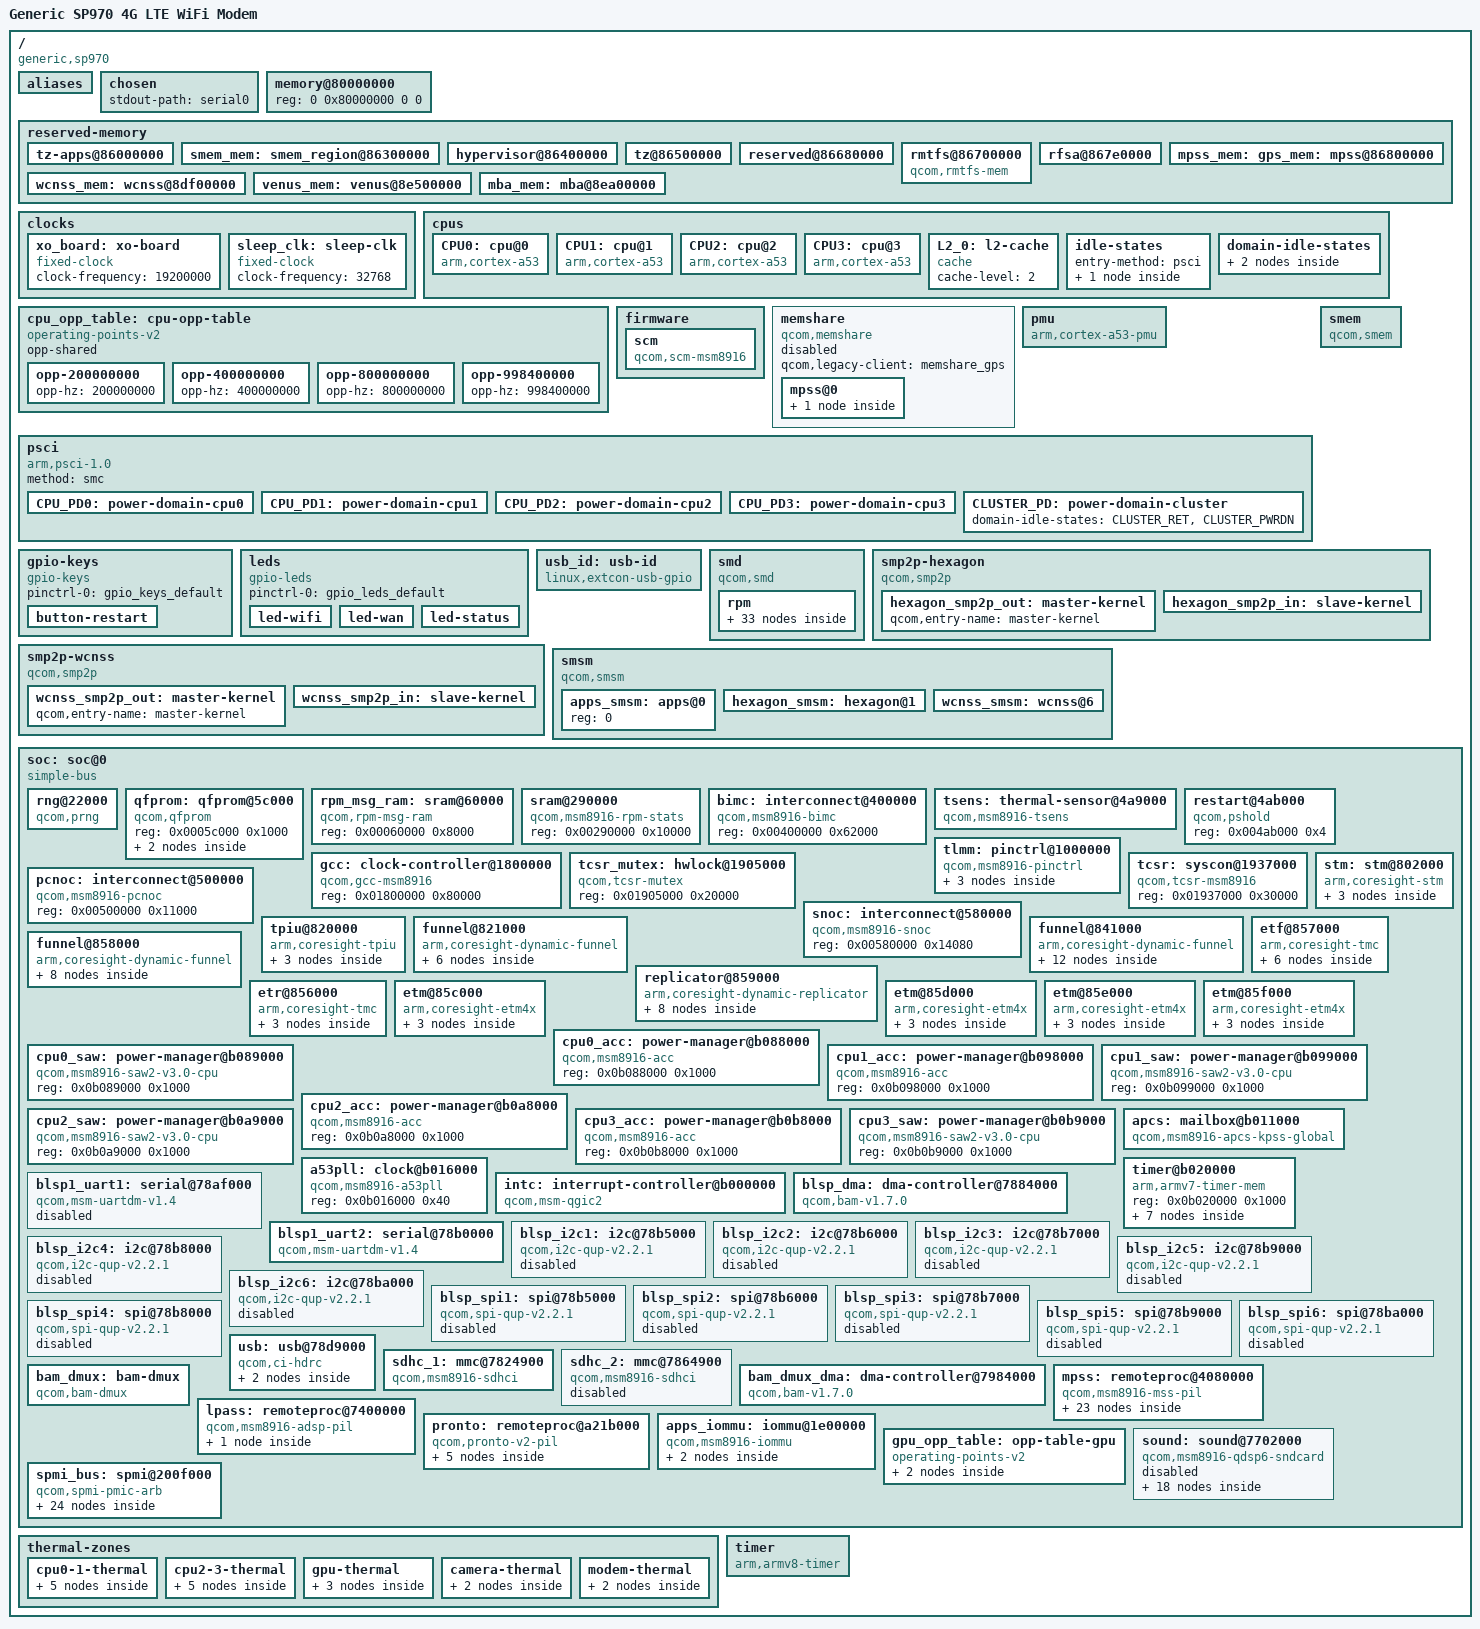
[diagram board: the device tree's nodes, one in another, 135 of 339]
// SPDX-License-Identifier: GPL-2.0-only

/dts-v1/;

#include <dt-bindings/clock/qcom,gcc-msm8916.h>
#include <dt-bindings/clock/qcom,rpmcc.h>
#include <dt-bindings/gpio/gpio.h>
#include <dt-bindings/input/input.h>
#include <dt-bindings/interrupt-controller/arm-gic.h>
#include <dt-bindings/leds/common.h>
#include <dt-bindings/pinctrl/qcom,pmic-gpio.h>
#include <dt-bindings/power/qcom-rpmpd.h>
#include <dt-bindings/reset/qcom,gcc-msm8916.h>
#include <dt-bindings/sound/apq8016-lpass.h>
#include <dt-bindings/sound/qcom,q6afe.h>
#include <dt-bindings/sound/qcom,q6asm.h>
#include <dt-bindings/sound/qcom,q6voice.h>
#include <dt-bindings/spmi/spmi.h>
#include <dt-bindings/thermal/thermal.h>

/ {
	model = "Generic SP970 4G LTE WiFi Modem";
	compatible = "generic,sp970", "qcom,msm8916";
	chassis-type = "embedded";

	interrupt-parent = <&intc>;
	#address-cells = <2>;
	#size-cells = <2>;

	aliases {
		serial0 = &blsp1_uart2;
		mmc0 = &sdhc_1;
		sdhc1 = &sdhc_1;
		sdhc2 = &sdhc_2;
	};

	chosen {
		stdout-path = "serial0";
	};

	memory@80000000 {
		device_type = "memory";
		reg = <0 0x80000000 0 0>;
	};

	reserved-memory {
		#address-cells = <2>;
		#size-cells = <2>;
		ranges;

		tz-apps@86000000 {
			reg = <0x0 0x86000000 0x0 0x300000>;
			no-map;
		};

		smem_mem: smem_region@86300000 {
			reg = <0x0 0x86300000 0x0 0x100000>;
			no-map;
		};

		hypervisor@86400000 {
			reg = <0x0 0x86400000 0x0 0x100000>;
			no-map;
		};

		tz@86500000 {
			reg = <0x0 0x86500000 0x0 0x180000>;
			no-map;
		};

		reserved@86680000 {
			reg = <0x0 0x86680000 0x0 0x80000>;
			no-map;
		};

		rmtfs@86700000 {
			compatible = "qcom,rmtfs-mem";
			reg = <0x0 0x86700000 0x0 0xe0000>;
			no-map;
			qcom,client-id = <1>;
		};

		rfsa@867e0000 {
			reg = <0x0 0x867e0000 0x0 0x20000>;
			no-map;
		};

		/* SP970 custom memory allocation for modem+GPS */
		mpss_mem: gps_mem: mpss@86800000 {
			reg = <0x0 0x86800000 0x0 0x5500000>;
			no-map;
		};

		wcnss_mem: wcnss@8df00000 {
			reg = <0x0 0x8df00000 0x0 0x600000>;
			no-map;
		};

		venus_mem: venus@8e500000 {
			reg = <0x0 0x8e500000 0x0 0x500000>;
			no-map;
		};

		mba_mem: mba@8ea00000 {
			reg = <0x0 0x8ea00000 0x0 0x100000>;
			no-map;
		};
	};

	clocks {
		xo_board: xo-board {
			compatible = "fixed-clock";
			#clock-cells = <0>;
			clock-frequency = <19200000>;
		};

		sleep_clk: sleep-clk {
			compatible = "fixed-clock";
			#clock-cells = <0>;
			clock-frequency = <32768>;
		};
	};

	cpus {
		#address-cells = <1>;
		#size-cells = <0>;

		CPU0: cpu@0 {
			device_type = "cpu";
			compatible = "arm,cortex-a53";
			reg = <0x0>;
			next-level-cache = <&L2_0>;
			enable-method = "psci";
			clocks = <&apcs>;
			operating-points-v2 = <&cpu_opp_table>;
			#cooling-cells = <2>;
			power-domains = <&CPU_PD0>;
			power-domain-names = "psci";
			qcom,acc = <&cpu0_acc>;
			qcom,saw = <&cpu0_saw>;
		};

		CPU1: cpu@1 {
			device_type = "cpu";
			compatible = "arm,cortex-a53";
			reg = <0x1>;
			next-level-cache = <&L2_0>;
			enable-method = "psci";
			clocks = <&apcs>;
			operating-points-v2 = <&cpu_opp_table>;
			#cooling-cells = <2>;
			power-domains = <&CPU_PD1>;
			power-domain-names = "psci";
			qcom,acc = <&cpu1_acc>;
			qcom,saw = <&cpu1_saw>;
		};

		CPU2: cpu@2 {
			device_type = "cpu";
			compatible = "arm,cortex-a53";
			reg = <0x2>;
			next-level-cache = <&L2_0>;
			enable-method = "psci";
			clocks = <&apcs>;
			operating-points-v2 = <&cpu_opp_table>;
			#cooling-cells = <2>;
			power-domains = <&CPU_PD2>;
			power-domain-names = "psci";
			qcom,acc = <&cpu2_acc>;
			qcom,saw = <&cpu2_saw>;
		};

		CPU3: cpu@3 {
			device_type = "cpu";
			compatible = "arm,cortex-a53";
			reg = <0x3>;
			next-level-cache = <&L2_0>;
			enable-method = "psci";
			clocks = <&apcs>;
			operating-points-v2 = <&cpu_opp_table>;
			#cooling-cells = <2>;
			power-domains = <&CPU_PD3>;
			power-domain-names = "psci";
			qcom,acc = <&cpu3_acc>;
			qcom,saw = <&cpu3_saw>;
		};

		L2_0: l2-cache {
			compatible = "cache";
			cache-level = <2>;
		};

		idle-states {
			entry-method = "psci";

			CPU_SLEEP_0: cpu-sleep-0 {
				compatible = "arm,idle-state";
				idle-state-name = "standalone-power-collapse";
				arm,psci-suspend-param = <0x40000002>;
				entry-latency-us = <130>;
				exit-latency-us = <150>;
				min-residency-us = <2000>;
				local-timer-stop;
			};
		};

		domain-idle-states {
			CLUSTER_RET: cluster-retention {
				compatible = "domain-idle-state";
				arm,psci-suspend-param = <0x41000012>;
				entry-latency-us = <500>;
				exit-latency-us = <500>;
				min-residency-us = <2000>;
			};

			CLUSTER_PWRDN: cluster-gdhs {
				compatible = "domain-idle-state";
				arm,psci-suspend-param = <0x41000032>;
				entry-latency-us = <2000>;
				exit-latency-us = <2000>;
				min-residency-us = <6000>;
			};
		};
	};

	cpu_opp_table: cpu-opp-table {
		compatible = "operating-points-v2";
		opp-shared;

		opp-200000000 {
			opp-hz = /bits/ 64 <200000000>;
		};

		opp-400000000 {
			opp-hz = /bits/ 64 <400000000>;
		};

		opp-800000000 {
			opp-hz = /bits/ 64 <800000000>;
		};

		opp-998400000 {
			opp-hz = /bits/ 64 <998400000>;
		};
	};

	firmware {
		scm: scm {
			compatible = "qcom,scm-msm8916", "qcom,scm";
			clocks = <&gcc GCC_CRYPTO_CLK>,
				 <&gcc GCC_CRYPTO_AXI_CLK>,
				 <&gcc GCC_CRYPTO_AHB_CLK>;
			clock-names = "core", "bus", "iface";
			#reset-cells = <1>;
			qcom,dload-mode = <&tcsr 0x6100>;
		};
	};

	/*
	 * Memshare disabled for SP970:
	 * The modem firmware sends a "query_size" memshare request for client ID 1,
	 * but doesn't actually use it. GPS only works if memshare is disabled or
	 * returns an error to the request.
	 */
	memshare: memshare {
		compatible = "qcom,memshare";
		qcom,legacy-client = <&memshare_gps>;
		status = "disabled";

		#address-cells = <1>;
		#size-cells = <0>;

		mpss@0 {
			reg = <0>;
			qcom,qrtr-node = <0>;

			#address-cells = <1>;
			#size-cells = <0>;

			memshare_gps: gps@0 {
				reg = <0>;
			};
		};
	};

	pmu {
		compatible = "arm,cortex-a53-pmu";
		interrupts = <GIC_PPI 7 (GIC_CPU_MASK_SIMPLE(4) | IRQ_TYPE_LEVEL_HIGH)>;
	};

	psci {
		compatible = "arm,psci-1.0";
		method = "smc";

		CPU_PD0: power-domain-cpu0 {
			#power-domain-cells = <0>;
			power-domains = <&CLUSTER_PD>;
			domain-idle-states = <&CPU_SLEEP_0>;
		};

		CPU_PD1: power-domain-cpu1 {
			#power-domain-cells = <0>;
			power-domains = <&CLUSTER_PD>;
			domain-idle-states = <&CPU_SLEEP_0>;
		};

		CPU_PD2: power-domain-cpu2 {
			#power-domain-cells = <0>;
			power-domains = <&CLUSTER_PD>;
			domain-idle-states = <&CPU_SLEEP_0>;
		};

		CPU_PD3: power-domain-cpu3 {
			#power-domain-cells = <0>;
			power-domains = <&CLUSTER_PD>;
			domain-idle-states = <&CPU_SLEEP_0>;
		};

		CLUSTER_PD: power-domain-cluster {
			#power-domain-cells = <0>;
			domain-idle-states = <&CLUSTER_RET>, <&CLUSTER_PWRDN>;
		};
	};

	/* SP970 specific hardware */
	gpio-keys {
		compatible = "gpio-keys";
		pinctrl-names = "default";
		pinctrl-0 = <&gpio_keys_default>;

		button-restart {
			label = "Restart";
			gpios = <&tlmm 107 GPIO_ACTIVE_LOW>;
			linux,code = <KEY_RESTART>;
			debounce-interval = <15>;
		};
	};

	leds {
		compatible = "gpio-leds";
		pinctrl-names = "default";
		pinctrl-0 = <&gpio_leds_default>;

		led-wifi {
			color = <LED_COLOR_ID_BLUE>;
			function = LED_FUNCTION_WLAN;
			gpios = <&tlmm 28 GPIO_ACTIVE_HIGH>;
			linux,default-trigger = "phy0tx";
			default-state = "off";
		};

		led-wan {
			color = <LED_COLOR_ID_GREEN>;
			function = LED_FUNCTION_WAN;
			gpios = <&tlmm 10 GPIO_ACTIVE_HIGH>;
			default-state = "off";
		};

		led-status {
			color = <LED_COLOR_ID_RED>;
			function = LED_FUNCTION_STATUS;
			gpios = <&tlmm 9 GPIO_ACTIVE_HIGH>;
			linux,default-trigger = "heartbeat";
			default-state = "on";
		};
	};

	usb_id: usb-id {
		compatible = "linux,extcon-usb-gpio";
		id-gpios = <&tlmm 110 GPIO_ACTIVE_HIGH>;
		pinctrl-names = "default";
		pinctrl-0 = <&usb_id_default>;
	};

	smd {
		compatible = "qcom,smd";

		rpm {
			interrupts = <GIC_SPI 168 IRQ_TYPE_EDGE_RISING>;
			qcom,ipc = <&apcs 8 0>;
			qcom,smd-edge = <15>;

			rpm_requests: rpm-requests {
				compatible = "qcom,rpm-msm8916";
				qcom,smd-channels = "rpm_requests";

				rpmcc: clock-controller {
					compatible = "qcom,rpmcc-msm8916", "qcom,rpmcc";
					#clock-cells = <1>;
				};

				rpmpd: power-controller {
					compatible = "qcom,msm8916-rpmpd";
					#power-domain-cells = <1>;
					operating-points-v2 = <&rpmpd_opp_table>;

					rpmpd_opp_table: opp-table {
						compatible = "operating-points-v2";

						rpmpd_opp_ret: opp1 {
							opp-level = <RPM_SMD_LEVEL_RETENTION>;
						};

						rpmpd_opp_ret_plus: opp2 {
							opp-level = <RPM_SMD_LEVEL_RETENTION_PLUS>;
						};

						rpmpd_opp_min_svs: opp3 {
							opp-level = <RPM_SMD_LEVEL_MIN_SVS>;
						};

						rpmpd_opp_low_svs: opp4 {
							opp-level = <RPM_SMD_LEVEL_LOW_SVS>;
						};

						rpmpd_opp_svs: opp5 {
							opp-level = <RPM_SMD_LEVEL_SVS>;
						};

						rpmpd_opp_svs_plus: opp6 {
							opp-level = <RPM_SMD_LEVEL_SVS_PLUS>;
						};

						rpmpd_opp_nom: opp7 {
							opp-level = <RPM_SMD_LEVEL_NOM>;
						};

						rpmpd_opp_nom_plus: opp8 {
							opp-level = <RPM_SMD_LEVEL_NOM_PLUS>;
						};

						rpmpd_opp_turbo: opp9 {
							opp-level = <RPM_SMD_LEVEL_TURBO>;
						};
					};
				};

				smd_rpm_regulators: pm8916-regulators {
					compatible = "qcom,rpm-pm8916-regulators";
					
					vdd_l1_l2_l3-supply = <&pm8916_s3>;
					vdd_l4_l5_l6-supply = <&pm8916_s4>;
					vdd_l7-supply = <&pm8916_s4>;

					pm8916_s3: s3 {
						regulator-min-microvolt = <1200000>;
						regulator-max-microvolt = <1300000>;
					};

					pm8916_s4: s4 {
						regulator-min-microvolt = <1800000>;
						regulator-max-microvolt = <2100000>;
					};

					pm8916_l1: l1 {
						regulator-min-microvolt = <1225000>;
						regulator-max-microvolt = <1225000>;
					};

					pm8916_l2: l2 {
						regulator-min-microvolt = <1200000>;
						regulator-max-microvolt = <1200000>;
					};

					pm8916_l4: l4 {
						regulator-min-microvolt = <2050000>;
						regulator-max-microvolt = <2050000>;
					};

					pm8916_l5: l5 {
						regulator-min-microvolt = <1800000>;
						regulator-max-microvolt = <1800000>;
					};

					pm8916_l6: l6 {
						regulator-min-microvolt = <1800000>;
						regulator-max-microvolt = <1800000>;
					};

					pm8916_l7: l7 {
						regulator-min-microvolt = <1800000>;
						regulator-max-microvolt = <1800000>;
					};

					pm8916_l8: l8 {
						regulator-min-microvolt = <2850000>;
						regulator-max-microvolt = <2900000>;
					};

					pm8916_l9: l9 {
						regulator-min-microvolt = <3300000>;
						regulator-max-microvolt = <3300000>;
					};

					pm8916_l10: l10 {
						regulator-min-microvolt = <2700000>;
						regulator-max-microvolt = <2800000>;
					};

					pm8916_l11: l11 {
						regulator-min-microvolt = <1800000>;
						regulator-max-microvolt = <2950000>;
						regulator-allow-set-load;
						regulator-system-load = <200000>;
					};

					pm8916_l12: l12 {
						regulator-min-microvolt = <1800000>;
						regulator-max-microvolt = <2950000>;
					};

					pm8916_l13: l13 {
						regulator-min-microvolt = <3075000>;
						regulator-max-microvolt = <3075000>;
					};

					pm8916_l14: l14 {
						regulator-min-microvolt = <1800000>;
						regulator-max-microvolt = <3300000>;
					};

					pm8916_l15: l15 {
						regulator-min-microvolt = <1800000>;
						regulator-max-microvolt = <3300000>;
					};

					pm8916_l16: l16 {
						regulator-min-microvolt = <1800000>;
						regulator-max-microvolt = <3300000>;
					};

					pm8916_l17: l17 {
						regulator-min-microvolt = <2850000>;
						regulator-max-microvolt = <2850000>;
						regulator-always-on;
					};

					pm8916_l18: l18 {
						regulator-min-microvolt = <2700000>;
						regulator-max-microvolt = <2700000>;
					};
				};
			};
		};
	};

	smem {
		compatible = "qcom,smem";
		memory-region = <&smem_mem>;
		qcom,rpm-msg-ram = <&rpm_msg_ram>;
		hwlocks = <&tcsr_mutex 3>;
	};

	smp2p-hexagon {
		compatible = "qcom,smp2p";
		qcom,smem = <435>, <428>;
		interrupts = <GIC_SPI 27 IRQ_TYPE_EDGE_RISING>;
		qcom,ipc = <&apcs 8 14>;
		qcom,local-pid = <0>;
		qcom,remote-pid = <1>;

		hexagon_smp2p_out: master-kernel {
			qcom,entry-name = "master-kernel";
			#qcom,smem-state-cells = <1>;
		};

		hexagon_smp2p_in: slave-kernel {
			qcom,entry-name = "slave-kernel";
			interrupt-controller;
			#interrupt-cells = <2>;
		};
	};

	smp2p-wcnss {
		compatible = "qcom,smp2p";
		qcom,smem = <451>, <431>;
		interrupts = <GIC_SPI 143 IRQ_TYPE_EDGE_RISING>;
		qcom,ipc = <&apcs 8 18>;
		qcom,local-pid = <0>;
		qcom,remote-pid = <4>;

		wcnss_smp2p_out: master-kernel {
			qcom,entry-name = "master-kernel";
			#qcom,smem-state-cells = <1>;
		};

		wcnss_smp2p_in: slave-kernel {
			qcom,entry-name = "slave-kernel";
			interrupt-controller;
			#interrupt-cells = <2>;
		};
	};

	smsm {
		compatible = "qcom,smsm";
		#address-cells = <1>;
		#size-cells = <0>;
		qcom,ipc-1 = <&apcs 8 13>;
		qcom,ipc-3 = <&apcs 8 19>;

		apps_smsm: apps@0 {
			reg = <0>;
			#qcom,smem-state-cells = <1>;
		};

		hexagon_smsm: hexagon@1 {
			reg = <1>;
			interrupts = <GIC_SPI 26 IRQ_TYPE_EDGE_RISING>;
			interrupt-controller;
			#interrupt-cells = <2>;
		};

		wcnss_smsm: wcnss@6 {
			reg = <6>;
			interrupts = <GIC_SPI 144 IRQ_TYPE_EDGE_RISING>;
			interrupt-controller;
			#interrupt-cells = <2>;
		};
	};

	soc: soc@0 {
		compatible = "simple-bus";
		#address-cells = <1>;
		#size-cells = <1>;
		ranges = <0 0 0 0xffffffff>;

		rng@22000 {
			compatible = "qcom,prng";
			reg = <0x00022000 0x200>;
			clocks = <&gcc GCC_PRNG_AHB_CLK>;
			clock-names = "core";
		};

		qfprom: qfprom@5c000 {
			compatible = "qcom,qfprom";
			reg = <0x0005c000 0x1000>;
			#address-cells = <1>;
			#size-cells = <1>;

			tsens_caldata: caldata@d0 {
				reg = <0xd0 0x8>;
			};

			tsens_calsel: calsel@ec {
				reg = <0xec 0x4>;
			};
		};

		rpm_msg_ram: sram@60000 {
			compatible = "qcom,rpm-msg-ram";
			reg = <0x00060000 0x8000>;
		};

		sram@290000 {
			compatible = "qcom,msm8916-rpm-stats";
			reg = <0x00290000 0x10000>;
		};

		bimc: interconnect@400000 {
			compatible = "qcom,msm8916-bimc";
			reg = <0x00400000 0x62000>;
			#interconnect-cells = <1>;
		};

		tsens: thermal-sensor@4a9000 {
			compatible = "qcom,msm8916-tsens", "qcom,tsens-v0_1";
			reg = <0x004a9000 0x1000>,
			      <0x004a8000 0x1000>;
			nvmem-cells = <&tsens_caldata>, <&tsens_calsel>;
			nvmem-cell-names = "calib", "calib_sel";
			#qcom,sensors = <5>;
			interrupts = <GIC_SPI 184 IRQ_TYPE_LEVEL_HIGH>;
			interrupt-names = "uplow";
			#thermal-sensor-cells = <1>;
		};

		restart@4ab000 {
			compatible = "qcom,pshold";
			reg = <0x004ab000 0x4>;
		};

		tlmm: pinctrl@1000000 {
			compatible = "qcom,msm8916-pinctrl";
			reg = <0x01000000 0x300000>;
			interrupts = <GIC_SPI 208 IRQ_TYPE_LEVEL_HIGH>;
			gpio-controller;
			gpio-ranges = <&tlmm 0 0 122>;
			#gpio-cells = <2>;
			interrupt-controller;
			#interrupt-cells = <2>;

			/* SP970 specific pinctrl states */
			gpio_keys_default: gpio-keys-default-state {
				pins = "gpio107";
				function = "gpio";
				drive-strength = <2>;
				bias-pull-up;
			};

			gpio_leds_default: gpio-leds-default-state {
				pins = "gpio9", "gpio10", "gpio28";
				function = "gpio";
				drive-strength = <2>;
				bias-disable;
			};

			usb_id_default: usb-id-default-state {
				pins = "gpio110";
				function = "gpio";
				drive-strength = <8>;
				bias-pull-up;
			};
		};

		gcc: clock-controller@1800000 {
			compatible = "qcom,gcc-msm8916";
			#clock-cells = <1>;
			#reset-cells = <1>;
			#power-domain-cells = <1>;
			reg = <0x01800000 0x80000>;
		};

		tcsr_mutex: hwlock@1905000 {
			compatible = "qcom,tcsr-mutex";
			reg = <0x01905000 0x20000>;
			#hwlock-cells = <1>;
		};

		tcsr: syscon@1937000 {
			compatible = "qcom,tcsr-msm8916", "syscon";
			reg = <0x01937000 0x30000>;
		};

		pcnoc: interconnect@500000 {
			compatible = "qcom,msm8916-pcnoc";
			reg = <0x00500000 0x11000>;
			#interconnect-cells = <1>;
		};

		snoc: interconnect@580000 {
			compatible = "qcom,msm8916-snoc";
			reg = <0x00580000 0x14080>;
			#interconnect-cells = <1>;
		};

		stm: stm@802000 {
			compatible = "arm,coresight-stm", "arm,primecell";
			reg = <0x00802000 0x1000>,
			      <0x09280000 0x180000>;
			reg-names = "stm-base", "stm-stimulus-base";
			clocks = <&rpmcc RPM_QDSS_CLK>, <&rpmcc RPM_QDSS_A_CLK>;
			clock-names = "apb_pclk", "atclk";

			out-ports {
				port {
					stm_out: endpoint {
						remote-endpoint = <&funnel0_in7>;
					};
				};
			};
		};

		tpiu@820000 {
			compatible = "arm,coresight-tpiu", "arm,primecell";
			reg = <0x00820000 0x1000>;
			clocks = <&rpmcc RPM_QDSS_CLK>, <&rpmcc RPM_QDSS_A_CLK>;
			clock-names = "apb_pclk", "atclk";

			in-ports {
				port {
					tpiu_in: endpoint {
						remote-endpoint = <&replicator_out1>;
					};
				};
			};
		};

		funnel@821000 {
			compatible = "arm,coresight-dynamic-funnel", "arm,primecell";
			reg = <0x00821000 0x1000>;
			clocks = <&rpmcc RPM_QDSS_CLK>, <&rpmcc RPM_QDSS_A_CLK>;
			clock-names = "apb_pclk", "atclk";

			in-ports {
				#address-cells = <1>;
				#size-cells = <0>;

				port@7 {
					reg = <7>;
					funnel0_in7: endpoint {
						remote-endpoint = <&stm_out>;
					};
				};
			};

			out-ports {
				port {
					funnel0_out: endpoint {
						remote-endpoint = <&merge_funnel_in0>;
					};
				};
			};
		};

		funnel@841000 {
			compatible = "arm,coresight-dynamic-funnel", "arm,primecell";
			reg = <0x00841000 0x1000>;
			clocks = <&rpmcc RPM_QDSS_CLK>, <&rpmcc RPM_QDSS_A_CLK>;
			clock-names = "apb_pclk", "atclk";

			in-ports {
				#address-cells = <1>;
				#size-cells = <0>;

				port@4 {
					reg = <4>;
					funnel1_in4: endpoint {
						remote-endpoint = <&etm3_out>;
					};
				};

				port@5 {
					reg = <5>;
					funnel1_in5: endpoint {
						remote-endpoint = <&etm2_out>;
					};
				};

				port@6 {
					reg = <6>;
					funnel1_in6: endpoint {
						remote-endpoint = <&etm1_out>;
					};
				};

				port@7 {
					reg = <7>;
					funnel1_in7: endpoint {
						remote-endpoint = <&etm0_out>;
					};
				};
			};

			out-ports {
				port {
					funnel1_out: endpoint {
						remote-endpoint = <&merge_funnel_in1>;
					};
				};
			};
		};

		funnel@858000 {
			compatible = "arm,coresight-dynamic-funnel", "arm,primecell";
			reg = <0x00858000 0x1000>;
			clocks = <&rpmcc RPM_QDSS_CLK>, <&rpmcc RPM_QDSS_A_CLK>;
			clock-names = "apb_pclk", "atclk";

			in-ports {
				#address-cells = <1>;
				#size-cells = <0>;

				port@0 {
					reg = <0>;
					merge_funnel_in0: endpoint {
						remote-endpoint = <&funnel0_out>;
					};
				};

				port@1 {
					reg = <1>;
					merge_funnel_in1: endpoint {
						remote-endpoint = <&funnel1_out>;
					};
				};
			};

			out-ports {
				port {
					merge_funnel_out: endpoint {
						remote-endpoint = <&etf_in>;
					};
				};
			};
		};

		replicator@859000 {
			compatible = "arm,coresight-dynamic-replicator", "arm,primecell";
			reg = <0x00859000 0x1000>;
			clocks = <&rpmcc RPM_QDSS_CLK>, <&rpmcc RPM_QDSS_A_CLK>;
			clock-names = "apb_pclk", "atclk";

			in-ports {
				port {
					replicator_in: endpoint {
						remote-endpoint = <&etf_out>;
					};
				};
			};

			out-ports {
				#address-cells = <1>;
				#size-cells = <0>;

				port@0 {
					reg = <0>;
					replicator_out0: endpoint {
						remote-endpoint = <&etr_in>;
					};
				};

				port@1 {
					reg = <1>;
					replicator_out1: endpoint {
						remote-endpoint = <&tpiu_in>;
					};
				};
			};
		};

		etf@857000 {
			compatible = "arm,coresight-tmc", "arm,primecell";
			reg = <0x00857000 0x1000>;
			clocks = <&rpmcc RPM_QDSS_CLK>, <&rpmcc RPM_QDSS_A_CLK>;
			clock-names = "apb_pclk", "atclk";

			in-ports {
				port {
					etf_in: endpoint {
						remote-endpoint = <&merge_funnel_out>;
					};
				};
			};

			out-ports {
				port {
					etf_out: endpoint {
						remote-endpoint = <&replicator_in>;
					};
				};
			};
		};

		etr@856000 {
			compatible = "arm,coresight-tmc", "arm,primecell";
			reg = <0x00856000 0x1000>;
			clocks = <&rpmcc RPM_QDSS_CLK>, <&rpmcc RPM_QDSS_A_CLK>;
			clock-names = "apb_pclk", "atclk";

			in-ports {
				port {
					etr_in: endpoint {
						remote-endpoint = <&replicator_out0>;
					};
				};
			};
		};

		etm@85c000 {
			compatible = "arm,coresight-etm4x", "arm,primecell";
			reg = <0x0085c000 0x1000>;
			clocks = <&rpmcc RPM_QDSS_CLK>, <&rpmcc RPM_QDSS_A_CLK>;
			clock-names = "apb_pclk", "atclk";
			cpu = <&CPU0>;

			out-ports {
				port {
					etm0_out: endpoint {
						remote-endpoint = <&funnel1_in7>;
					};
				};
			};
		};

		etm@85d000 {
			compatible = "arm,coresight-etm4x", "arm,primecell";
			reg = <0x0085d000 0x1000>;
			clocks = <&rpmcc RPM_QDSS_CLK>, <&rpmcc RPM_QDSS_A_CLK>;
			clock-names = "apb_pclk", "atclk";
			cpu = <&CPU1>;

			out-ports {
				port {
					etm1_out: endpoint {
						remote-endpoint = <&funnel1_in6>;
					};
				};
			};
		};

		etm@85e000 {
			compatible = "arm,coresight-etm4x", "arm,primecell";
			reg = <0x0085e000 0x1000>;
			clocks = <&rpmcc RPM_QDSS_CLK>, <&rpmcc RPM_QDSS_A_CLK>;
			clock-names = "apb_pclk", "atclk";
			cpu = <&CPU2>;

			out-ports {
				port {
					etm2_out: endpoint {
						remote-endpoint = <&funnel1_in5>;
					};
				};
			};
		};

		etm@85f000 {
			compatible = "arm,coresight-etm4x", "arm,primecell";
			reg = <0x0085f000 0x1000>;
			clocks = <&rpmcc RPM_QDSS_CLK>, <&rpmcc RPM_QDSS_A_CLK>;
			clock-names = "apb_pclk", "atclk";
			cpu = <&CPU3>;

			out-ports {
				port {
					etm3_out: endpoint {
						remote-endpoint = <&funnel1_in4>;
					};
				};
			};
		};

		cpu0_acc: power-manager@b088000 {
			compatible = "qcom,msm8916-acc";
			reg = <0x0b088000 0x1000>;
		};

		cpu0_saw: power-manager@b089000 {
			compatible = "qcom,msm8916-saw2-v3.0-cpu", "qcom,saw2";
			reg = <0x0b089000 0x1000>;
		};

		cpu1_acc: power-manager@b098000 {
			compatible = "qcom,msm8916-acc";
			reg = <0x0b098000 0x1000>;
		};

		cpu1_saw: power-manager@b099000 {
			compatible = "qcom,msm8916-saw2-v3.0-cpu", "qcom,saw2";
			reg = <0x0b099000 0x1000>;
		};

		cpu2_acc: power-manager@b0a8000 {
			compatible = "qcom,msm8916-acc";
			reg = <0x0b0a8000 0x1000>;
		};

		cpu2_saw: power-manager@b0a9000 {
			compatible = "qcom,msm8916-saw2-v3.0-cpu", "qcom,saw2";
			reg = <0x0b0a9000 0x1000>;
		};

		cpu3_acc: power-manager@b0b8000 {
			compatible = "qcom,msm8916-acc";
			reg = <0x0b0b8000 0x1000>;
		};

		cpu3_saw: power-manager@b0b9000 {
			compatible = "qcom,msm8916-saw2-v3.0-cpu", "qcom,saw2";
			reg = <0x0b0b9000 0x1000>;
		};

		apcs: mailbox@b011000 {
			compatible = "qcom,msm8916-apcs-kpss-global", "syscon";
			reg = <0x0b011000 0x1000>;
			#mbox-cells = <1>;
			clocks = <&a53pll>, <&gcc GPLL0_VOTE>;
			clock-names = "pll", "aux";
			#clock-cells = <0>;
		};

		a53pll: clock@b016000 {
			compatible = "qcom,msm8916-a53pll";
			reg = <0x0b016000 0x40>;
			#clock-cells = <0>;
		};

		timer@b020000 {
			compatible = "arm,armv7-timer-mem";
			reg = <0x0b020000 0x1000>;
			#address-cells = <1>;
			#size-cells = <1>;
			ranges;

			frame@b021000 {
				reg = <0x0b021000 0x1000>,
				      <0x0b022000 0x1000>;
				frame-number = <0>;
				interrupts = <GIC_SPI 8 IRQ_TYPE_LEVEL_HIGH>,
					     <GIC_SPI 7 IRQ_TYPE_LEVEL_HIGH>;
			};

			frame@b023000 {
				reg = <0x0b023000 0x1000>;
				frame-number = <1>;
				interrupts = <GIC_SPI 9 IRQ_TYPE_LEVEL_HIGH>;
				status = "disabled";
			};

			frame@b024000 {
				reg = <0x0b024000 0x1000>;
				frame-number = <2>;
				interrupts = <GIC_SPI 10 IRQ_TYPE_LEVEL_HIGH>;
				status = "disabled";
			};

			frame@b025000 {
				reg = <0x0b025000 0x1000>;
				frame-number = <3>;
				interrupts = <GIC_SPI 11 IRQ_TYPE_LEVEL_HIGH>;
				status = "disabled";
			};

			frame@b026000 {
				reg = <0x0b026000 0x1000>;
				frame-number = <4>;
				interrupts = <GIC_SPI 12 IRQ_TYPE_LEVEL_HIGH>;
				status = "disabled";
			};

			frame@b027000 {
				reg = <0x0b027000 0x1000>;
				frame-number = <5>;
				interrupts = <GIC_SPI 13 IRQ_TYPE_LEVEL_HIGH>;
				status = "disabled";
			};

			frame@b028000 {
				reg = <0x0b028000 0x1000>;
				frame-number = <6>;
				interrupts = <GIC_SPI 14 IRQ_TYPE_LEVEL_HIGH>;
				status = "disabled";
			};
		};

		intc: interrupt-controller@b000000 {
			compatible = "qcom,msm-qgic2";
			reg = <0x0b000000 0x1000>, <0x0b002000 0x1000>;
			interrupt-controller;
			#interrupt-cells = <3>;
		};

		blsp_dma: dma-controller@7884000 {
			compatible = "qcom,bam-v1.7.0";
			reg = <0x07884000 0x1f000>;
			interrupts = <GIC_SPI 238 IRQ_TYPE_LEVEL_HIGH>;
			clocks = <&gcc GCC_BLSP1_AHB_CLK>;
			clock-names = "bam_clk";
			#dma-cells = <1>;
			qcom,ee = <0>;
			status = "okay";
		};

		blsp1_uart1: serial@78af000 {
			compatible = "qcom,msm-uartdm-v1.4", "qcom,msm-uartdm";
			reg = <0x078af000 0x200>;
			interrupts = <GIC_SPI 107 IRQ_TYPE_LEVEL_HIGH>;
			clocks = <&gcc GCC_BLSP1_UART1_APPS_CLK>, <&gcc GCC_BLSP1_AHB_CLK>;
			clock-names = "core", "iface";
			dmas = <&blsp_dma 0>, <&blsp_dma 1>;
			dma-names = "tx", "rx";
			status = "disabled";
		};

		blsp1_uart2: serial@78b0000 {
			compatible = "qcom,msm-uartdm-v1.4", "qcom,msm-uartdm";
			reg = <0x078b0000 0x200>;
			interrupts = <GIC_SPI 108 IRQ_TYPE_LEVEL_HIGH>;
			clocks = <&gcc GCC_BLSP1_UART2_APPS_CLK>, <&gcc GCC_BLSP1_AHB_CLK>;
			clock-names = "core", "iface";
			dmas = <&blsp_dma 2>, <&blsp_dma 3>;
			dma-names = "tx", "rx";
			status = "okay";
		};

		blsp_i2c1: i2c@78b5000 {
			compatible = "qcom,i2c-qup-v2.2.1";
			reg = <0x078b5000 0x500>;
			interrupts = <GIC_SPI 95 IRQ_TYPE_LEVEL_HIGH>;
			clocks = <&gcc GCC_BLSP1_QUP1_I2C_APPS_CLK>,
				 <&gcc GCC_BLSP1_AHB_CLK>;
			clock-names = "core", "iface";
			dmas = <&blsp_dma 4>, <&blsp_dma 5>;
			dma-names = "tx", "rx";
			pinctrl-names = "default", "sleep";
			pinctrl-0 = <&i2c1_default>;
			pinctrl-1 = <&i2c1_sleep>;
			#address-cells = <1>;
			#size-cells = <0>;
			status = "disabled";
		};

		blsp_i2c2: i2c@78b6000 {
			compatible = "qcom,i2c-qup-v2.2.1";
			reg = <0x078b6000 0x500>;
			interrupts = <GIC_SPI 96 IRQ_TYPE_LEVEL_HIGH>;
			clocks = <&gcc GCC_BLSP1_QUP2_I2C_APPS_CLK>,
				 <&gcc GCC_BLSP1_AHB_CLK>;
			clock-names = "core", "iface";
			dmas = <&blsp_dma 6>, <&blsp_dma 7>;
			dma-names = "tx", "rx";
			pinctrl-names = "default", "sleep";
			pinctrl-0 = <&i2c2_default>;
			pinctrl-1 = <&i2c2_sleep>;
			#address-cells = <1>;
			#size-cells = <0>;
			status = "disabled";
		};

		blsp_i2c3: i2c@78b7000 {
			compatible = "qcom,i2c-qup-v2.2.1";
			reg = <0x078b7000 0x500>;
			interrupts = <GIC_SPI 97 IRQ_TYPE_LEVEL_HIGH>;
			clocks = <&gcc GCC_BLSP1_QUP3_I2C_APPS_CLK>,
				 <&gcc GCC_BLSP1_AHB_CLK>;
			clock-names = "core", "iface";
			dmas = <&blsp_dma 8>, <&blsp_dma 9>;
			dma-names = "tx", "rx";
			pinctrl-names = "default", "sleep";
			pinctrl-0 = <&i2c3_default>;
			pinctrl-1 = <&i2c3_sleep>;
			#address-cells = <1>;
			#size-cells = <0>;
			status = "disabled";
		};

		blsp_i2c4: i2c@78b8000 {
			compatible = "qcom,i2c-qup-v2.2.1";
			reg = <0x078b8000 0x500>;
			interrupts = <GIC_SPI 98 IRQ_TYPE_LEVEL_HIGH>;
			clocks = <&gcc GCC_BLSP1_QUP4_I2C_APPS_CLK>,
				 <&gcc GCC_BLSP1_AHB_CLK>;
			clock-names = "core", "iface";
			dmas = <&blsp_dma 10>, <&blsp_dma 11>;
			dma-names = "tx", "rx";
			pinctrl-names = "default", "sleep";
			pinctrl-0 = <&i2c4_default>;
			pinctrl-1 = <&i2c4_sleep>;
			#address-cells = <1>;
			#size-cells = <0>;
			status = "disabled";
		};

		blsp_i2c5: i2c@78b9000 {
			compatible = "qcom,i2c-qup-v2.2.1";
			reg = <0x078b9000 0x500>;
			interrupts = <GIC_SPI 99 IRQ_TYPE_LEVEL_HIGH>;
			clocks = <&gcc GCC_BLSP1_QUP5_I2C_APPS_CLK>,
				 <&gcc GCC_BLSP1_AHB_CLK>;
			clock-names = "core", "iface";
			dmas = <&blsp_dma 12>, <&blsp_dma 13>;
			dma-names = "tx", "rx";
			pinctrl-names = "default", "sleep";
			pinctrl-0 = <&i2c5_default>;
			pinctrl-1 = <&i2c5_sleep>;
			#address-cells = <1>;
			#size-cells = <0>;
			status = "disabled";
		};

		blsp_i2c6: i2c@78ba000 {
			compatible = "qcom,i2c-qup-v2.2.1";
			reg = <0x078ba000 0x500>;
			interrupts = <GIC_SPI 100 IRQ_TYPE_LEVEL_HIGH>;
			clocks = <&gcc GCC_BLSP1_QUP6_I2C_APPS_CLK>,
				 <&gcc GCC_BLSP1_AHB_CLK>;
			clock-names = "core", "iface";
			dmas = <&blsp_dma 14>, <&blsp_dma 15>;
			dma-names = "tx", "rx";
			pinctrl-names = "default", "sleep";
			pinctrl-0 = <&i2c6_default>;
			pinctrl-1 = <&i2c6_sleep>;
			#address-cells = <1>;
			#size-cells = <0>;
			status = "disabled";
		};

		blsp_spi1: spi@78b5000 {
			compatible = "qcom,spi-qup-v2.2.1";
			reg = <0x078b5000 0x500>;
			interrupts = <GIC_SPI 95 IRQ_TYPE_LEVEL_HIGH>;
			clocks = <&gcc GCC_BLSP1_QUP1_SPI_APPS_CLK>,
				 <&gcc GCC_BLSP1_AHB_CLK>;
			clock-names = "core", "iface";
			dmas = <&blsp_dma 4>, <&blsp_dma 5>;
			dma-names = "tx", "rx";
			pinctrl-names = "default", "sleep";
			pinctrl-0 = <&spi1_default>;
			pinctrl-1 = <&spi1_sleep>;
			#address-cells = <1>;
			#size-cells = <0>;
			status = "disabled";
		};

		blsp_spi2: spi@78b6000 {
			compatible = "qcom,spi-qup-v2.2.1";
			reg = <0x078b6000 0x500>;
			interrupts = <GIC_SPI 96 IRQ_TYPE_LEVEL_HIGH>;
			clocks = <&gcc GCC_BLSP1_QUP2_SPI_APPS_CLK>,
				 <&gcc GCC_BLSP1_AHB_CLK>;
			clock-names = "core", "iface";
			dmas = <&blsp_dma 6>, <&blsp_dma 7>;
			dma-names = "tx", "rx";
			pinctrl-names = "default", "sleep";
			pinctrl-0 = <&spi2_default>;
			pinctrl-1 = <&spi2_sleep>;
			#address-cells = <1>;
			#size-cells = <0>;
			status = "disabled";
		};

		blsp_spi3: spi@78b7000 {
			compatible = "qcom,spi-qup-v2.2.1";
			reg = <0x078b7000 0x500>;
			interrupts = <GIC_SPI 97 IRQ_TYPE_LEVEL_HIGH>;
			clocks = <&gcc GCC_BLSP1_QUP3_SPI_APPS_CLK>,
				 <&gcc GCC_BLSP1_AHB_CLK>;
			clock-names = "core", "iface";
			dmas = <&blsp_dma 8>, <&blsp_dma 9>;
			dma-names = "tx", "rx";
			pinctrl-names = "default", "sleep";
			pinctrl-0 = <&spi3_default>;
			pinctrl-1 = <&spi3_sleep>;
			#address-cells = <1>;
			#size-cells = <0>;
			status = "disabled";
		};

		blsp_spi4: spi@78b8000 {
			compatible = "qcom,spi-qup-v2.2.1";
			reg = <0x078b8000 0x500>;
			interrupts = <GIC_SPI 98 IRQ_TYPE_LEVEL_HIGH>;
			clocks = <&gcc GCC_BLSP1_QUP4_SPI_APPS_CLK>,
				 <&gcc GCC_BLSP1_AHB_CLK>;
			clock-names = "core", "iface";
			dmas = <&blsp_dma 10>, <&blsp_dma 11>;
			dma-names = "tx", "rx";
			pinctrl-names = "default", "sleep";
			pinctrl-0 = <&spi4_default>;
			pinctrl-1 = <&spi4_sleep>;
			#address-cells = <1>;
			#size-cells = <0>;
			status = "disabled";
		};

		blsp_spi5: spi@78b9000 {
			compatible = "qcom,spi-qup-v2.2.1";
			reg = <0x078b9000 0x500>;
			interrupts = <GIC_SPI 99 IRQ_TYPE_LEVEL_HIGH>;
			clocks = <&gcc GCC_BLSP1_QUP5_SPI_APPS_CLK>,
				 <&gcc GCC_BLSP1_AHB_CLK>;
			clock-names = "core", "iface";
			dmas = <&blsp_dma 12>, <&blsp_dma 13>;
			dma-names = "tx", "rx";
			pinctrl-names = "default", "sleep";
			pinctrl-0 = <&spi5_default>;
			pinctrl-1 = <&spi5_sleep>;
			#address-cells = <1>;
			#size-cells = <0>;
			status = "disabled";
		};

		blsp_spi6: spi@78ba000 {
			compatible = "qcom,spi-qup-v2.2.1";
			reg = <0x078ba000 0x500>;
			interrupts = <GIC_SPI 100 IRQ_TYPE_LEVEL_HIGH>;
			clocks = <&gcc GCC_BLSP1_QUP6_SPI_APPS_CLK>,
				 <&gcc GCC_BLSP1_AHB_CLK>;
			clock-names = "core", "iface";
			dmas = <&blsp_dma 14>, <&blsp_dma 15>;
			dma-names = "tx", "rx";
			pinctrl-names = "default", "sleep";
			pinctrl-0 = <&spi6_default>;
			pinctrl-1 = <&spi6_sleep>;
			#address-cells = <1>;
			#size-cells = <0>;
			status = "disabled";
		};

		usb: usb@78d9000 {
			compatible = "qcom,ci-hdrc";
			reg = <0x078d9000 0x200>,
			      <0x078d9200 0x200>;
			interrupts = <GIC_SPI 134 IRQ_TYPE_LEVEL_HIGH>,
				     <GIC_SPI 140 IRQ_TYPE_LEVEL_HIGH>;
			clocks = <&gcc GCC_USB_HS_AHB_CLK>, <&gcc GCC_USB_HS_SYSTEM_CLK>;
			clock-names = "iface", "core";
			assigned-clocks = <&gcc GCC_USB_HS_SYSTEM_CLK>;
			assigned-clock-rates = <80000000>;
			resets = <&gcc GCC_USB_HS_BCR>;
			reset-names = "core";
			phy_type = "ulpi";
			dr_mode = "otg";
			hnp-disable;
			srp-disable;
			adp-disable;
			ahb-burst-config = <0>;
			phy-names = "usb-phy";
			phys = <&usb_hs_phy>;
			status = "okay";
			extcon = <&usb_id>, <&usb_id>;

			#reset-cells = <1>;

			ulpi {
				usb_hs_phy: phy {
					compatible = "qcom,usb-hs-phy-msm8916", "qcom,usb-hs-phy";
					#phy-cells = <0>;
					clocks = <&xo_board>, <&gcc GCC_USB2A_PHY_SLEEP_CLK>;
					clock-names = "ref", "sleep";
					resets = <&gcc GCC_USB2A_PHY_BCR>;
					reset-names = "phy";
					v1p8-supply = <&pm8916_l7>;
					v3p3-supply = <&pm8916_l13>;
					extcon = <&usb_id>;
				};
			};
		};

		sdhc_1: mmc@7824900 {
			compatible = "qcom,msm8916-sdhci", "qcom,sdhci-msm-v4";
			reg = <0x07824900 0x11c>, <0x07824000 0x800>;
			reg-names = "hc", "core";
			interrupts = <GIC_SPI 123 IRQ_TYPE_LEVEL_HIGH>,
				     <GIC_SPI 138 IRQ_TYPE_LEVEL_HIGH>;
			interrupt-names = "hc_irq", "pwr_irq";
			clocks = <&gcc GCC_SDCC1_AHB_CLK>,
				 <&gcc GCC_SDCC1_APPS_CLK>,
				 <&xo_board>;
			clock-names = "iface", "core", "xo";
			bus-width = <8>;
			non-removable;
			vmmc-supply = <&pm8916_l8>;
			vqmmc-supply = <&pm8916_l5>;
			status = "okay";
			pinctrl-names = "default", "sleep";
			pinctrl-0 = <&sdc1_clk_on &sdc1_cmd_on &sdc1_data_on>;
			pinctrl-1 = <&sdc1_clk_off &sdc1_cmd_off &sdc1_data_off>;
		};

		sdhc_2: mmc@7864900 {
			compatible = "qcom,msm8916-sdhci", "qcom,sdhci-msm-v4";
			reg = <0x07864900 0x11c>, <0x07864000 0x800>;
			reg-names = "hc", "core";
			interrupts = <GIC_SPI 125 IRQ_TYPE_LEVEL_HIGH>,
				     <GIC_SPI 221 IRQ_TYPE_LEVEL_HIGH>;
			interrupt-names = "hc_irq", "pwr_irq";
			clocks = <&gcc GCC_SDCC2_AHB_CLK>,
				 <&gcc GCC_SDCC2_APPS_CLK>,
				 <&xo_board>;
			clock-names = "iface", "core", "xo";
			bus-width = <4>;
			vmmc-supply = <&pm8916_l11>;
			vqmmc-supply = <&pm8916_l12>;
			status = "disabled";
		};

		bam_dmux_dma: dma-controller@7984000 {
			compatible = "qcom,bam-v1.7.0";
			reg = <0x07984000 0x1f000>;
			interrupts = <GIC_SPI 94 IRQ_TYPE_LEVEL_HIGH>;
			clocks = <&gcc GCC_SYS_NOC_USB3_AXI_CLK>;
			clock-names = "bam_clk";
			#dma-cells = <1>;
			qcom,ee = <0>;
			qcom,controlled-remotely;
			num-channels = <6>;
			qcom,num-ees = <2>;
			status = "okay";
		};

		bam_dmux: bam-dmux {
			compatible = "qcom,bam-dmux";
			interrupts = <GIC_SPI 29 IRQ_TYPE_EDGE_RISING>;
			interrupt-names = "pc";
			qcom,smem-states = <&apps_smsm 1>, <&apps_smsm 11>;
			qcom,smem-state-names = "power-control", "ssr";
			dmas = <&bam_dmux_dma 4>, <&bam_dmux_dma 5>;
			dma-names = "tx", "rx";
			status = "okay";
		};

		mpss: remoteproc@4080000 {
			compatible = "qcom,msm8916-mss-pil";
			reg = <0x04080000 0x100>,
			      <0x04020000 0x040>;
			reg-names = "qdsp6", "rmb";
			interrupts-extended = <&intc GIC_SPI 24 IRQ_TYPE_EDGE_RISING>,
					      <&hexagon_smp2p_in 0 IRQ_TYPE_EDGE_RISING>,
					      <&hexagon_smp2p_in 1 IRQ_TYPE_EDGE_RISING>,
					      <&hexagon_smp2p_in 2 IRQ_TYPE_EDGE_RISING>,
					      <&hexagon_smp2p_in 3 IRQ_TYPE_EDGE_RISING>;
			interrupt-names = "wdog", "fatal", "ready", "handover", "stop-ack";
			power-domains = <&rpmpd MSM8916_VDDCX>, <&rpmpd MSM8916_VDDMX>;
			power-domain-names = "cx", "mx";
			clocks = <&gcc GCC_MSS_CFG_AHB_CLK>,
				 <&gcc GCC_MSS_Q6_BIMC_AXI_CLK>,
				 <&gcc GCC_BOOT_ROM_AHB_CLK>,
				 <&xo_board>;
			clock-names = "iface", "bus", "mem", "xo";
			qcom,smem-states = <&hexagon_smp2p_out 0>;
			qcom,smem-state-names = "stop";
			resets = <&scm MSM8916_QDSP6_RESET>;
			reset-names = "mss_restart";
			qcom,halt-regs = <&tcsr 0x18000 0x19000 0x1a000>;
			pll-supply = <&pm8916_l7>;
			status = "okay";

			mba {
				memory-region = <&mba_mem>;
			};

			mpss {
				memory-region = <&mpss_mem>;
			};

			smd-edge {
				interrupts = <GIC_SPI 25 IRQ_TYPE_EDGE_RISING>;
				qcom,smd-edge = <0>;
				qcom,ipc = <&apcs 8 12>;
				qcom,remote-pid = <1>;
				label = "hexagon";

				apr: apr {
					compatible = "qcom,apr-v2";
					qcom,smd-channels = "apr_audio_svc";
					qcom,domain = <APR_DOMAIN_ADSP>;
					#address-cells = <1>;
					#size-cells = <0>;
					status = "okay";

					q6core: service@3 {
						compatible = "qcom,q6core";
						reg = <APR_SVC_ADSP_CORE>;
					};

					q6afe: service@4 {
						compatible = "qcom,q6afe";
						reg = <APR_SVC_AFE>;
						q6afedai: dais {
							compatible = "qcom,q6afe-dais";
							#address-cells = <1>;
							#size-cells = <0>;
							#sound-dai-cells = <1>;

							dai@16 {
								reg = <PRIMARY_MI2S_RX>;
								qcom,sd-lines = <0 1>;
							};

							dai@20 {
								reg = <TERTIARY_MI2S_TX>;
								qcom,sd-lines = <0 1>;
							};
						};
					};

					q6asm: service@7 {
						compatible = "qcom,q6asm";
						reg = <APR_SVC_ASM>;
						q6asmdai: dais {
							compatible = "qcom,q6asm-dais";
							#address-cells = <1>;
							#size-cells = <0>;
							#sound-dai-cells = <1>;
							iommus = <&apps_iommu 1>;

							dai@0 {
								reg = <0>;
								direction = <Q6ASM_DAI_RX>;
							};

							dai@1 {
								reg = <1>;
								direction = <Q6ASM_DAI_TX>;
							};

							dai@2 {
								reg = <2>;
								direction = <Q6ASM_DAI_RX>;
							};

							dai@3 {
								reg = <3>;
								direction = <Q6ASM_DAI_RX>;
								is-compress-dai;
							};
						};
					};

					q6adm: service@8 {
						compatible = "qcom,q6adm";
						reg = <APR_SVC_ADM>;
						q6routing: routing {
							compatible = "qcom,q6adm-routing";
							#sound-dai-cells = <0>;
						};
					};

					q6voice: service@9 {
						compatible = "qcom,q6voice";
						reg = <APR_SVC_VOICE>;
						q6voicedai: dais {
							compatible = "qcom,q6voice-dais";
							#sound-dai-cells = <1>;
						};
					};
				};

				fastrpc {
					compatible = "qcom,fastrpc";
					qcom,smd-channels = "fastrpcsmd-apps-dsp";
					label = "adsp";
					qcom,non-secure-domain;
					#address-cells = <1>;
					#size-cells = <0>;

					compute-cb@1 {
						compatible = "qcom,fastrpc-compute-cb";
						reg = <1>;
						iommus = <&apps_iommu 1>;
					};

					compute-cb@2 {
						compatible = "qcom,fastrpc-compute-cb";
						reg = <2>;
						iommus = <&apps_iommu 2>;
					};

					compute-cb@3 {
						compatible = "qcom,fastrpc-compute-cb";
						reg = <3>;
						iommus = <&apps_iommu 3>;
						/* note: shared-cb */
					};
				};
			};
		};

		lpass: remoteproc@7400000 {
			compatible = "qcom,msm8916-adsp-pil";
			reg = <0x07400000 0x100>;
			interrupts-extended = <&intc GIC_SPI 162 IRQ_TYPE_EDGE_RISING>,
					      <&hexagon_smp2p_in 0 IRQ_TYPE_EDGE_RISING>,
					      <&hexagon_smp2p_in 1 IRQ_TYPE_EDGE_RISING>,
					      <&hexagon_smp2p_in 2 IRQ_TYPE_EDGE_RISING>,
					      <&hexagon_smp2p_in 3 IRQ_TYPE_EDGE_RISING>;
			interrupt-names = "wdog", "fatal", "ready", "handover", "stop-ack";
			power-domains = <&rpmpd MSM8916_VDDCX>;
			power-domain-names = "cx";
			clocks = <&gcc GCC_PRNG_AHB_CLK>;
			clock-names = "xo";
			qcom,smem-states = <&hexagon_smp2p_out 0>;
			qcom,smem-state-names = "stop";
			memory-region = <&mpss_mem>;
			qcom,halt-regs = <&tcsr 0x18000>;
			status = "okay";

			lpass_codec: audio-codec {
				compatible = "qcom,msm8916-codec-analog";
				reg = <0x0771c000 0x400>;
				#sound-dai-cells = <1>;
				clocks = <&gcc GCC_CODEC_DIGCODEC_CLK>;
				clock-names = "mclk";
				interrupt-parent = <&spmi_bus>;
				interrupts = <0x1 0xf0 0x0 IRQ_TYPE_NONE>,
					     <0x1 0xf0 0x1 IRQ_TYPE_NONE>,
					     <0x1 0xf0 0x2 IRQ_TYPE_NONE>,
					     <0x1 0xf0 0x3 IRQ_TYPE_NONE>,
					     <0x1 0xf0 0x4 IRQ_TYPE_NONE>,
					     <0x1 0xf0 0x5 IRQ_TYPE_NONE>,
					     <0x1 0xf0 0x6 IRQ_TYPE_NONE>,
					     <0x1 0xf0 0x7 IRQ_TYPE_NONE>;
			};
		};

		pronto: remoteproc@a21b000 {
			compatible = "qcom,pronto-v2-pil", "qcom,pronto";
			reg = <0x0a21b000 0x3000>,
			      <0x0a204000 0x2000>,
			      <0x0a202000 0x1000>,
			      <0x0a200000 0x2000>;
			reg-names = "ccu", "dxe", "pmu", "spare";
			interrupts-extended = <&intc GIC_SPI 149 IRQ_TYPE_EDGE_RISING>,
					      <&wcnss_smp2p_in 0 IRQ_TYPE_EDGE_RISING>,
					      <&wcnss_smp2p_in 1 IRQ_TYPE_EDGE_RISING>,
					      <&wcnss_smp2p_in 2 IRQ_TYPE_EDGE_RISING>,
					      <&wcnss_smp2p_in 3 IRQ_TYPE_EDGE_RISING>;
			interrupt-names = "wdog", "fatal", "ready", "handover", "stop-ack";
			power-domains = <&rpmpd MSM8916_VDDCX>, <&rpmpd MSM8916_VDDMX>;
			power-domain-names = "cx", "mx";
			clocks = <&gcc GCC_PRNG_AHB_CLK>, <&xo_board>;
			clock-names = "xo", "ref";
			qcom,smem-states = <&wcnss_smp2p_out 0>;
			qcom,smem-state-names = "stop";
			memory-region = <&wcnss_mem>;
			qcom,state = <&wcnss_smsm 0>;
			qcom,state-names = "stop";
			vddpx-supply = <&pm8916_l7>;
			status = "okay";

			iris {
				compatible = "qcom,wcn3660b";
				clocks = <&rpmcc RPM_SMD_RF_CLK2>;
				clock-names = "xo";
				vddxo-supply = <&pm8916_l7>;
				vddrfa-supply = <&pm8916_s3>;
				vddpa-supply = <&pm8916_l9>;
				vdddig-supply = <&pm8916_l5>;
			};

			smd-edge {
				interrupts = <GIC_SPI 142 IRQ_TYPE_EDGE_RISING>;
				qcom,smd-edge = <6>;
				qcom,ipc = <&apcs 8 17>;
				qcom,remote-pid = <4>;
				label = "pronto";

				wcnss {
					compatible = "qcom,wcnss";
					qcom,smd-channels = "WCNSS_CTRL";

					qcom,mmio = <&pronto>;

					wcnss_bt: bluetooth {
						compatible = "qcom,wcnss-bt";
					};

					wcnss_wifi: wifi {
						compatible = "qcom,wcnss-wlan";
						interrupts = <GIC_SPI 145 IRQ_TYPE_LEVEL_HIGH>,
							     <GIC_SPI 146 IRQ_TYPE_LEVEL_HIGH>;
						interrupt-names = "tx", "rx";
						qcom,smem-states = <&apps_smsm 10>, <&apps_smsm 9>;
						qcom,smem-state-names = "tx-enable", "tx-rings-empty";
					};
				};
			};
		};

		apps_iommu: iommu@1e00000 {
			compatible = "qcom,msm8916-iommu", "qcom,msm-iommu-v1";
			ranges = <0 0x01e00000 0x40000>;
			clocks = <&gcc GCC_SMMU_CFG_CLK>,
				 <&gcc GCC_APSS_TCU_CLK>;
			clock-names = "iface", "bus";
			qcom,iommu-secure-id = <17>;
			#address-cells = <1>;
			#size-cells = <1>;
			#iommu-cells = <1>;

			/* mdp_0 */
			iommu-ctx@4000 {
				compatible = "qcom,msm-iommu-v1-ns";
				reg = <0x4000 0x1000>;
				interrupts = <GIC_SPI 70 IRQ_TYPE_LEVEL_HIGH>;
			};

			/* venus_ns */
			iommu-ctx@5000 {
				compatible = "qcom,msm-iommu-v1-sec";
				reg = <0x5000 0x1000>;
				interrupts = <GIC_SPI 69 IRQ_TYPE_LEVEL_HIGH>;
			};
		};

		gpu_opp_table: opp-table-gpu {
			compatible = "operating-points-v2";

			opp-400000000 {
				opp-hz = /bits/ 64 <400000000>;
			};

			opp-19200000 {
				opp-hz = /bits/ 64 <19200000>;
			};
		};

		sound: sound@7702000 {
			compatible = "qcom,msm8916-qdsp6-sndcard";
			model = "msm8916";
			reg = <0x07702000 0x4>,
			      <0x07702004 0x4>;
			reg-names = "mic-iomux", "spkr-iomux";
			status = "disabled";

			pinctrl-names = "default", "sleep";
			pinctrl-0 = <&cdc_pdm_lines_act>;
			pinctrl-1 = <&cdc_pdm_lines_sus>;

			dai-link-multimedia1 {
				link-name = "MultiMedia1";
				cpu {
					sound-dai = <&q6asmdai MSM_FRONTEND_DAI_MULTIMEDIA1>;
				};
			};

			dai-link-multimedia2 {
				link-name = "MultiMedia2";
				cpu {
					sound-dai = <&q6asmdai MSM_FRONTEND_DAI_MULTIMEDIA2>;
				};
			};

			dai-link-multimedia3 {
				link-name = "MultiMedia3";
				cpu {
					sound-dai = <&q6asmdai MSM_FRONTEND_DAI_MULTIMEDIA3>;
				};
			};

			dai-link-multimedia4 {
				link-name = "MultiMedia4";
				cpu {
					sound-dai = <&q6asmdai MSM_FRONTEND_DAI_MULTIMEDIA4>;
				};
			};

			dai-link-cs-voice {
				link-name = "CS-Voice";
				cpu {
					sound-dai = <&q6voicedai CS_VOICE>;
				};
			};

			sound_dai_primary: dai-link-primary {
				link-name = "Primary MI2S";
				cpu {
					sound-dai = <&q6afedai PRIMARY_MI2S_RX>;
				};

				platform {
					sound-dai = <&q6routing>;
				};

				codec {
					sound-dai = <&lpass_codec 0>, <&wcd_codec 0>;
				};
			};

			sound_dai_tertiary: dai-link-tertiary {
				link-name = "Tertiary MI2S";
				cpu {
					sound-dai = <&q6afedai TERTIARY_MI2S_TX>;
				};

				platform {
					sound-dai = <&q6routing>;
				};

				codec {
					sound-dai = <&lpass_codec 1>, <&wcd_codec 1>;
				};
			};
		};

		spmi_bus: spmi@200f000 {
			compatible = "qcom,spmi-pmic-arb";
			reg = <0x0200f000 0x1000>,
			      <0x02400000 0x400000>,
			      <0x02c00000 0x400000>,
			      <0x03800000 0x200000>,
			      <0x0200a000 0x2100>;
			reg-names = "core", "chnls", "obsrvr", "intr", "cnfg";
			interrupt-names = "periph_irq";
			interrupts = <GIC_SPI 190 IRQ_TYPE_LEVEL_HIGH>;
			qcom,ee = <0>;
			qcom,channel = <0>;
			#address-cells = <2>;
			#size-cells = <0>;
			interrupt-controller;
			#interrupt-cells = <4>;

			pm8916_0: pmic@0 {
				compatible = "qcom,pm8916", "qcom,spmi-pmic";
				reg = <0x0 SPMI_USID>;
				#address-cells = <1>;
				#size-cells = <0>;

				pon@800 {
					compatible = "qcom,pm8916-pon";
					reg = <0x800>;
					mode-bootloader = <0x2>;
					mode-recovery = <0x1>;

					pwrkey {
						compatible = "qcom,pm8941-pwrkey";
						interrupts = <0x0 0x8 0 IRQ_TYPE_EDGE_BOTH>;
						debounce = <15625>;
						bias-pull-up;
						linux,code = <KEY_POWER>;
					};

					pm8916_resin: resin {
						compatible = "qcom,pm8941-resin";
						interrupts = <0x0 0x8 1 IRQ_TYPE_EDGE_BOTH>;
						debounce = <15625>;
						bias-pull-up;
						status = "disabled";
					};

					watchdog {
						compatible = "qcom,pm8916-wdt";
						interrupts = <0x0 0x8 6 IRQ_TYPE_EDGE_RISING>;
						timeout-sec = <60>;
					};
				};

				pm8916_charger: charger@1000 {
					compatible = "qcom,pm8916-lbc";
					reg = <0x1000>, <0x1200>, <0x1300>, <0x1600>;
					interrupts = <0x0 0x13 1 IRQ_TYPE_EDGE_BOTH>;
					status = "disabled";
				};

				pm8916_usbin: extcon@1300 {
					compatible = "qcom,pm8941-misc";
					reg = <0x1300>;
					interrupts = <0x0 0x13 1 IRQ_TYPE_EDGE_BOTH>;
					interrupt-names = "usb_vbus";
					status = "disabled";
				};

				pm8916_temp: temp-alarm@2400 {
					compatible = "qcom,spmi-temp-alarm";
					reg = <0x2400>;
					interrupts = <0 0x24 0 IRQ_TYPE_EDGE_RISING>;
					io-channels = <&pm8916_vadc VADC_DIE_TEMP>;
					io-channel-names = "thermal";
					#thermal-sensor-cells = <0>;
				};

				pm8916_vadc: adc@3100 {
					compatible = "qcom,spmi-vadc";
					reg = <0x3100>;
					interrupts = <0x0 0x31 0x0 IRQ_TYPE_EDGE_RISING>;
					#address-cells = <1>;
					#size-cells = <0>;
					#io-channel-cells = <1>;

					adc-chan@0 {
						reg = <VADC_USBIN>;
						qcom,pre-scaling = <1 10>;
					};

					adc-chan@7 {
						reg = <VADC_VSYS>;
						qcom,pre-scaling = <1 3>;
					};

					adc-chan@8 {
						reg = <VADC_DIE_TEMP>;
					};

					adc-chan@9 {
						reg = <VADC_REF_625MV>;
					};

					adc-chan@a {
						reg = <VADC_REF_1250MV>;
					};

					adc-chan@e {
						reg = <VADC_GND_REF>;
					};

					adc-chan@f {
						reg = <VADC_VDD_VADC>;
					};
				};

				pm8916_bms: vm-bms@4000 {
					compatible = "qcom,pm8916-bms-vm";
					reg = <0x4000>;
					interrupts = <0x0 0x40 4 IRQ_TYPE_EDGE_RISING>;
					status = "disabled";
				};

				rtc@6000 {
					compatible = "qcom,pm8941-rtc";
					reg = <0x6000>, <0x6100>;
					reg-names = "rtc", "alarm";
					interrupts = <0x0 0x61 0x1 IRQ_TYPE_EDGE_RISING>;
				};

				pm8916_mpps: mpps@a000 {
					compatible = "qcom,pm8916-mpp";
					reg = <0xa000>;
					gpio-controller;
					#gpio-cells = <2>;
					interrupts = <0 0xa0 0 IRQ_TYPE_NONE>,
						     <0 0xa1 0 IRQ_TYPE_NONE>,
						     <0 0xa2 0 IRQ_TYPE_NONE>,
						     <0 0xa3 0 IRQ_TYPE_NONE>;
				};

				pm8916_gpios: gpios@c000 {
					compatible = "qcom,pm8916-gpio";
					reg = <0xc000>;
					gpio-controller;
					#gpio-cells = <2>;
					interrupts = <0 0xc0 0 IRQ_TYPE_NONE>,
						     <0 0xc1 0 IRQ_TYPE_NONE>,
						     <0 0xc2 0 IRQ_TYPE_NONE>,
						     <0 0xc3 0 IRQ_TYPE_NONE>;
				};
			};

			pm8916_1: pmic@1 {
				compatible = "qcom,pm8916", "qcom,spmi-pmic";
				reg = <0x1 SPMI_USID>;
				#address-cells = <1>;
				#size-cells = <0>;

				pm8916_pwm: pwm@bc00 {
					compatible = "qcom,pm8916-pwm";
					#pwm-cells = <2>;
					status = "disabled";
				};

				pm8916_vib: vibrator@c000 {
					compatible = "qcom,pm8916-vib";
					reg = <0xc000>;
					status = "disabled";
				};

				wcd_codec: audio-codec@f000 {
					compatible = "qcom,pm8916-wcd-analog-codec";
					reg = <0xf000>;
					reg-names = "pmic-codec-core";
					clocks = <&gcc GCC_CODEC_DIGCODEC_CLK>;
					clock-names = "mclk";
					interrupt-parent = <&spmi_bus>;
					interrupts = <0x1 0xf0 0x0 IRQ_TYPE_NONE>,
						     <0x1 0xf0 0x1 IRQ_TYPE_NONE>,
						     <0x1 0xf0 0x2 IRQ_TYPE_NONE>,
						     <0x1 0xf0 0x3 IRQ_TYPE_NONE>,
						     <0x1 0xf0 0x4 IRQ_TYPE_NONE>,
						     <0x1 0xf0 0x5 IRQ_TYPE_NONE>,
						     <0x1 0xf0 0x6 IRQ_TYPE_NONE>,
						     <0x1 0xf0 0x7 IRQ_TYPE_NONE>,
						     <0x1 0xf1 0x0 IRQ_TYPE_NONE>,
						     <0x1 0xf1 0x1 IRQ_TYPE_NONE>,
						     <0x1 0xf1 0x2 IRQ_TYPE_NONE>,
						     <0x1 0xf1 0x3 IRQ_TYPE_NONE>,
						     <0x1 0xf1 0x4 IRQ_TYPE_NONE>,
						     <0x1 0xf1 0x5 IRQ_TYPE_NONE>;
					interrupt-names = "cdc_spk_cnp_int",
							  "cdc_spk_clip_int",
							  "cdc_spk_ocp_int",
							  "mbhc_ins_rem_det1",
							  "mbhc_but_rel_det",
							  "mbhc_but_press_det",
							  "mbhc_ins_rem_det",
							  "mbhc_switch_int",
							  "cdc_ear_ocp_int",
							  "cdc_hphr_ocp_int",
							  "cdc_hphl_ocp_det",
							  "cdc_ear_cnp_int",
							  "cdc_hphr_cnp_int",
							  "cdc_hphl_cnp_int";
					vdd-cdc-io-supply = <&pm8916_l5>;
					vdd-cdc-tx-rx-cx-supply = <&pm8916_l5>;
					vdd-micbias-supply = <&pm8916_l13>;
					#sound-dai-cells = <1>;
				};
			};
		};
	};

	thermal-zones {
		cpu0-1-thermal {
			polling-delay-passive = <250>;
			polling-delay = <1000>;
			thermal-sensors = <&tsens 4>;

			trips {
				cpu0_1_alert0: trip-point0 {
					temperature = <75000>;
					hysteresis = <2000>;
					type = "passive";
				};

				cpu0_1_crit: crit {
					temperature = <110000>;
					hysteresis = <2000>;
					type = "critical";
				};
			};

			cooling-maps {
				map0 {
					trip = <&cpu0_1_alert0>;
					cooling-device = <&CPU0 THERMAL_NO_LIMIT THERMAL_NO_LIMIT>,
							 <&CPU1 THERMAL_NO_LIMIT THERMAL_NO_LIMIT>,
							 <&CPU2 THERMAL_NO_LIMIT THERMAL_NO_LIMIT>,
							 <&CPU3 THERMAL_NO_LIMIT THERMAL_NO_LIMIT>;
				};
			};
		};

		cpu2-3-thermal {
			polling-delay-passive = <250>;
			polling-delay = <1000>;
			thermal-sensors = <&tsens 5>;

			trips {
				cpu2_3_alert0: trip-point0 {
					temperature = <75000>;
					hysteresis = <2000>;
					type = "passive";
				};

				cpu2_3_crit: crit {
					temperature = <110000>;
					hysteresis = <2000>;
					type = "critical";
				};
			};

			cooling-maps {
				map0 {
					trip = <&cpu2_3_alert0>;
					cooling-device = <&CPU0 THERMAL_NO_LIMIT THERMAL_NO_LIMIT>,
							 <&CPU1 THERMAL_NO_LIMIT THERMAL_NO_LIMIT>,
							 <&CPU2 THERMAL_NO_LIMIT THERMAL_NO_LIMIT>,
							 <&CPU3 THERMAL_NO_LIMIT THERMAL_NO_LIMIT>;
				};
			};
		};

		gpu-thermal {
			polling-delay-passive = <250>;
			polling-delay = <1000>;
			thermal-sensors = <&tsens 2>;

			trips {
				gpu_alert0: trip-point0 {
					temperature = <75000>;
					hysteresis = <2000>;
					type = "passive";
				};

				gpu_crit: crit {
					temperature = <95000>;
					hysteresis = <2000>;
					type = "critical";
				};
			};
		};

		camera-thermal {
			polling-delay-passive = <250>;
			polling-delay = <1000>;
			thermal-sensors = <&tsens 1>;

			trips {
				cam_alert0: trip-point0 {
					temperature = <75000>;
					hysteresis = <2000>;
					type = "hot";
				};
			};
		};

		modem-thermal {
			polling-delay-passive = <250>;
			polling-delay = <1000>;
			thermal-sensors = <&tsens 0>;

			trips {
				modem_alert0: trip-point0 {
					temperature = <85000>;
					hysteresis = <2000>;
					type = "hot";
				};
			};
		};
	};

	timer {
		compatible = "arm,armv8-timer";
		interrupts = <GIC_PPI 2 (GIC_CPU_MASK_SIMPLE(4) | IRQ_TYPE_LEVEL_LOW)>,
			     <GIC_PPI 3 (GIC_CPU_MASK_SIMPLE(4) | IRQ_TYPE_LEVEL_LOW)>,
			     <GIC_PPI 4 (GIC_CPU_MASK_SIMPLE(4) | IRQ_TYPE_LEVEL_LOW)>,
			     <GIC_PPI 1 (GIC_CPU_MASK_SIMPLE(4) | IRQ_TYPE_LEVEL_LOW)>;
	};
};
